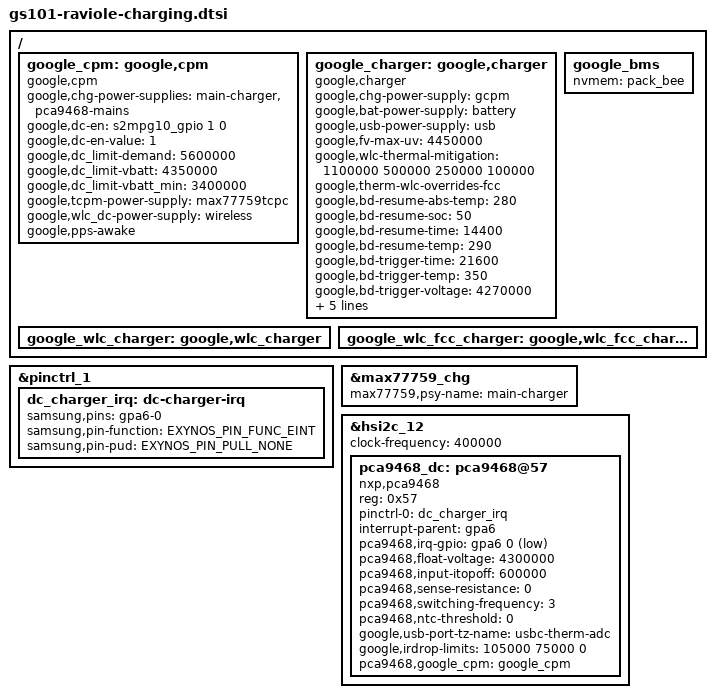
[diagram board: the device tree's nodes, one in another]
// SPDX-License-Identifier: GPL-2.0-only
/*
 * Battery device tree entries specific to raviole
 *
 * Copyright 2021 Google,LLC
 *
 */

/ {
	fragment@charging {
		target-path = "/";
		__overlay__ {

			google_cpm: google,cpm {
				status = "okay";
				compatible = "google,cpm";
				google,chg-power-supplies = "main-charger",
							    "pca9468-mains";

				/* S2MPG10X01 -> GPIO_1 -> CHARGE_PUMP_EN */
				google,dc-en = <&s2mpg10_gpio 1 0>;
				/* DC enabled by default */
				google,dc-en-value = <1>;
				google,dc_limit-demand = <5600000>;
				google,dc_limit-vbatt = <4350000>;
				google,dc_limit-vbatt_min = <3400000>;

				google,tcpm-power-supply = <&max77759tcpc>;
				google,wlc_dc-power-supply = "wireless";
				google,pps-awake;
			};

			google_charger: google,charger {
				status = "okay";
				compatible = "google,charger";
				#cooling-cells = <2>;

				google,chg-power-supply = "gcpm";
				google,bat-power-supply = "battery";
				google,usb-power-supply = "usb";

				google,fv-max-uv = <4450000>;

				google,wlc-thermal-mitigation = <1100000 500000 250000 100000>;
				google,therm-wlc-overrides-fcc;

				/* b/170700459 thresholds, updated in b/191070950 */
				google,bd-resume-abs-temp = <280>;
				google,bd-resume-soc = <50>;
				google,bd-resume-time = <14400>;  /* 4 hours */
				google,bd-resume-temp = <290>;
				google,bd-trigger-time = <21600>; /* 6 hours */
				google,bd-trigger-temp = <350>;
				google,bd-trigger-voltage = <4270000>;
				google,bd-recharge-voltage = <4250000>;
				google,bd-drainto-soc = <80>;
				google,bd-recharge-soc = <79>;
				/* Enable TEMP-DEFEND */
				google,bd-temp-enable;
				google,bd-temp-dry-run;
			};

			google_bms {
				nvmem = <&pack_bee>;
			};

			google_wlc_charger: google,wlc_charger {
				#cooling-cells = <2>;
			};

			google_wlc_fcc_charger: google,wlc_fcc_charger {
				#cooling-cells = <2>;
			};
		};
	};
};

&pinctrl_1 {

	dc_charger_irq: dc-charger-irq {
		samsung,pins = "gpa6-0"; /* XEINT_0 (PLC_INT_L) */
		samsung,pin-function = <EXYNOS_PIN_FUNC_EINT>;
		samsung,pin-pud = <EXYNOS_PIN_PULL_NONE>;
	};
};


&max77759_chg {
	max77759,psy-name = "main-charger";
};

&hsi2c_12 {

	#address-cells = <1>;
	#size-cells = <0>;
	status = "okay";
	clock-frequency = <400000>;

	pca9468_dc: pca9468@57 {
		compatible = "nxp,pca9468";
		reg = <0x57>;

		pinctrl-names = "default";
		pinctrl-0 = <&dc_charger_irq>;

		interrupt-parent = <&gpa6>;
		pca9468,irq-gpio = <&gpa6 0 GPIO_ACTIVE_LOW>; /* PLC_INT_L */

		pca9468,float-voltage = <4300000>; /* 4.3V */

		pca9468,input-itopoff = <600000>; /* 600mA */
		pca9468,sense-resistance = <0>; /* 5mOhm */
		pca9468,switching-frequency = <3>; /* 980KHz */

		/* disable USBC NTC */
		pca9468,ntc-threshold = <0>; /* disabled */

		/* USBC thermal zone */
		google,usb-port-tz-name = "usbc-therm-adc";

		/* irdrop */
		google,irdrop-limits = <105000 75000 0>;

		pca9468,google_cpm = <&google_cpm>;
	};

};
